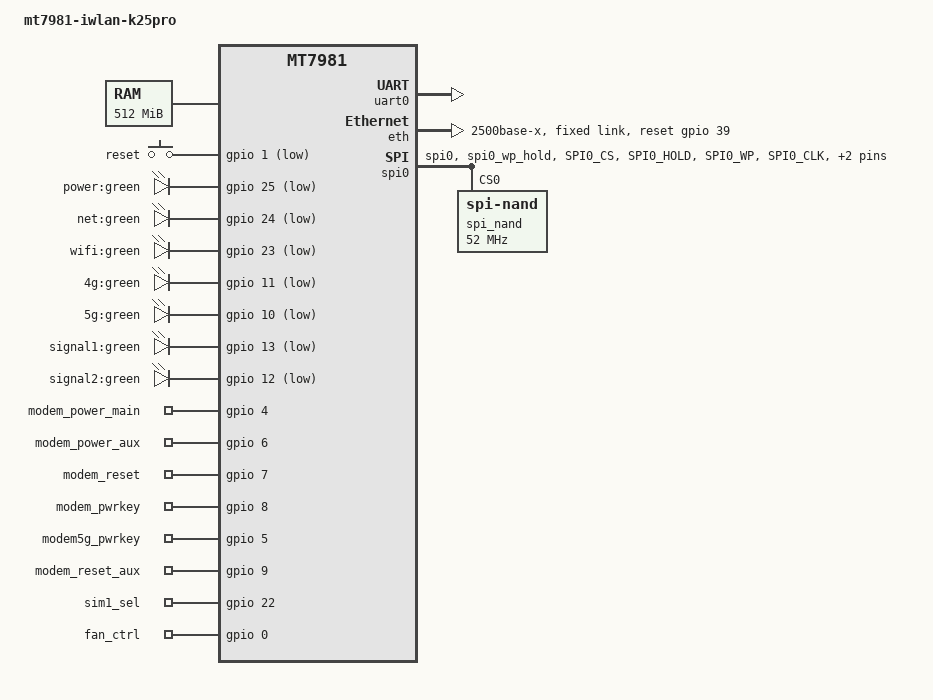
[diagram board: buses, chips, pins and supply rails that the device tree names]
/dts-v1/;
 
#include "mt7981.dtsi"
#include <dt-bindings/gpio/gpio.h>
#include <dt-bindings/input/input.h>
#include <dt-bindings/leds/common.h>
 
/ {
	#address-cells = <1>;
	#size-cells = <1>;
	model = "mt7981-iwlan-k25pro";
	compatible = "mediatek,mt7981", "mediatek,mt7981-rfb", "iwlan,k25pro";
 
	chosen {
		stdout-path = &uart0;
		tick-timer = &timer0;
	};
 
	config {
		bootcmd = "mtkboardboot";
		blink_led = "net:green";
		system_led = "power:green";
	};
 
	mtd-layout {
		layout@0 {
			label = "default";
			cmdline = "console=ttyS0,115200n1 loglevel=8 ubi.mtd=ubi";
			mtdids = "nmbm0=nmbm0";
			mtdparts = "nmbm0:1024k(bl2),512k(u-boot-env),2048k(factory),2048k(fip),-(ubi)";
		};
	};
 
	memory@40000000 {
		device_type = "memory";
		reg = <0x40000000 0x20000000>;
	};
 
	gpio-keys {
		compatible = "gpio-keys";
 
		reset-button {
			label = "reset";
			linux,code = <KEY_RESTART>;
			gpios = <&gpio 1 GPIO_ACTIVE_LOW>;
		};
	};
 
	leds {
		compatible = "gpio-leds";
 
		power {
			label = "power:green";
			gpios = <&gpio 25 GPIO_ACTIVE_LOW>;
			default-state = "on";
		};
 
		net {
			label = "net:green";
			gpios = <&gpio 24 GPIO_ACTIVE_LOW>;
		};
 
		wifi {
			label = "wifi:green";
			gpios = <&gpio 23 GPIO_ACTIVE_LOW>;
		};
 
		led4g {
			label = "4g:green";
			gpios = <&gpio 11 GPIO_ACTIVE_LOW>;
		};
 
		led5g {
			label = "5g:green";
			gpios = <&gpio 10 GPIO_ACTIVE_LOW>;
		};
 
		signal1 {
			label = "signal1:green";
			gpios = <&gpio 13 GPIO_ACTIVE_LOW>;
		};
 
		signal2 {
			label = "signal2:green";
			gpios = <&gpio 12 GPIO_ACTIVE_LOW>;
		};
	};
 
	gpio-export {
		compatible = "gpio-export";
		#size-cells = <0>;
 
		modem_power_main {
			gpio-export,name = "modem_power_main";
			gpio-export,output = <0>;
			gpios = <&gpio 4 GPIO_ACTIVE_HIGH>;
		};
 
		modem_power_aux {
			gpio-export,name = "modem_power_aux";
			gpio-export,output = <0>;
			gpios = <&gpio 6 GPIO_ACTIVE_HIGH>;
		};
 
		modem_reset {
			gpio-export,name = "modem_reset";
			gpio-export,output = <0>;
			gpios = <&gpio 7 GPIO_ACTIVE_HIGH>;
		};
 
		modem_pwrkey {
			gpio-export,name = "modem_pwrkey";
			gpio-export,output = <1>;
			gpios = <&gpio 8 GPIO_ACTIVE_HIGH>;
		};
 
		modem5g_pwrkey {
			gpio-export,name = "modem5g_pwrkey";
			gpio-export,output = <1>;
			gpios = <&gpio 5 GPIO_ACTIVE_HIGH>;
		};
 
		modem_reset_aux {
			gpio-export,name = "modem_reset_aux";
			gpio-export,output = <0>;
			gpios = <&gpio 9 GPIO_ACTIVE_HIGH>;
		};
 
		sim1_sel {
			gpio-export,name = "sim1_sel";
			gpio-export,output = <0>;
			gpios = <&gpio 22 GPIO_ACTIVE_HIGH>;
		};
 
		fan_ctrl {
			gpio-export,name = "fan_ctrl";
			gpio-export,output = <0>;
			gpios = <&gpio 0 GPIO_ACTIVE_HIGH>;
		};
	};
 
	bl2_verify {
		bl2_compatible = "spim-nand";
	};
};
 
&uart0 {
	status = "okay";
};
 
&eth {
	status = "okay";
	mediatek,gmac-id = <0>;
	phy-mode = "2500base-x";
	mediatek,switch = "mt7531";
	reset-gpios = <&gpio 39 GPIO_ACTIVE_HIGH>;
 
	fixed-link {
		speed = <2500>;
		full-duplex;
		pause;
	};
};
 
&pinctrl {
	spi_flash_pins: spi0-pins-func-1 {
		mux {
			function = "flash";
			groups = "spi0", "spi0_wp_hold";
		};
 
		conf-pu {
			pins = "SPI0_CS", "SPI0_HOLD", "SPI0_WP";
			drive-strength = <MTK_DRIVE_8mA>;
			bias-pull-up = <MTK_PUPD_SET_R1R0_11>;
		};
 
		conf-pd {
			pins = "SPI0_CLK", "SPI0_MOSI", "SPI0_MISO";
			drive-strength = <MTK_DRIVE_8mA>;
			bias-pull-down = <MTK_PUPD_SET_R1R0_11>;
		};
	};
};
 
&spi0 {
	#address-cells = <1>;
	#size-cells = <0>;
	pinctrl-names = "default";
	pinctrl-0 = <&spi_flash_pins>;
	status = "okay";
	must_tx;
	enhance_timing;
	dma_ext;
	ipm_design;
	support_quad;
	tick_dly = <2>;
	sample_sel = <0>;
 
	spi_nand@0 {
		compatible = "spi-nand";
		reg = <0>;
		spi-max-frequency = <52000000>;
	};
};
 
&spi1 {
	status = "disabled";
};
 
&watchdog {
	status = "disabled";
};
